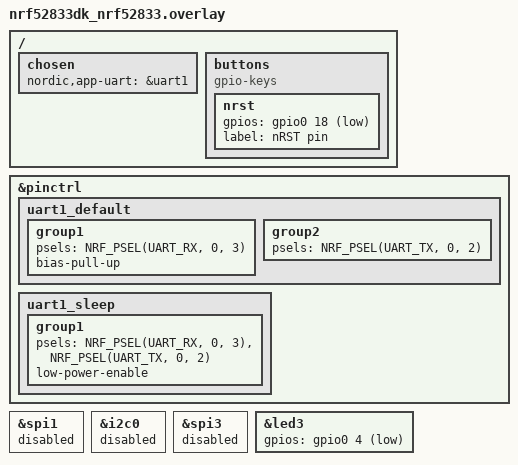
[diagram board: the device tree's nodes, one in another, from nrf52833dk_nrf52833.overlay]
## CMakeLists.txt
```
# SPDX-License-Identifier: Apache-2.0

cmake_minimum_required(VERSION 3.20.0)

set(CMAKE_EXPORT_COMPILE_COMMANDS ON)

# NOTE: Add module paths variable
set(QPC ${CMAKE_CURRENT_SOURCE_DIR}/qpc)                                    # QPC framework
set(APP_UART ${CMAKE_CURRENT_SOURCE_DIR}/ncs-uart-handler/modules/app_uart) # Async UART lib

# Append to Zephyr extra modules
#####################################################
find_package(Zephyr REQUIRED HINTS $ENV{ZEPHYR_BASE})
project(zephyr_obd)

target_sources(app PRIVATE src/main.c)

# Custom files and folders
target_sources(app PRIVATE
src/ble/bluetoothle.c
    
    src/ble/bluetoothle.c
    src/ble/ble_gatt.c
    src/driver/hal.c
    src/driver/hal_adc.c
    src/driver/hal_gpio.c
    src/driver/hal_i2c.c
    src/driver/hal_pwm.c
    src/driver/hal_uart.c
)

zephyr_library_include_directories(src/ble)
zephyr_library_include_directories(src/driver)
```

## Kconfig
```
source "Kconfig.zephyr"

config BOARD_ENABLE_FEM
bool "FEM enabled"
default y
select MPSL_FEM_GENERIC_TWO_CTRL_PINS_SUPPORT
```

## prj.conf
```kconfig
# Enable compiler output color
CONFIG_COMPILER_COLOR_DIAGNOSTICS=y

# Stack size configs
CONFIG_SYSTEM_WORKQUEUE_STACK_SIZE=3072
CONFIG_MAIN_STACK_SIZE=4096
CONFIG_ISR_STACK_SIZE=4096
# Debug configs
CONFIG_ASSERT=y
CONFIG_RESET_ON_FATAL_ERROR=n

CONFIG_DEBUG=y
CONFIG_DEBUG_OPTIMIZATIONS=y
CONFIG_DEBUG_THREAD_INFO=y

CONFIG_THREAD_NAME=y
CONFIG_THREAD_ANALYZER=y

CONFIG_TRACING=y
CONFIG_TRACING_BACKEND_RAM=y

CONFIG_SEGGER_SYSTEMVIEW=y
CONFIG_USE_SEGGER_RTT=y

# Logger configs
CONFIG_LOG=y
CONFIG_LOG_MODE_IMMEDIATE=y
CONFIG_LOG_BACKEND_RTT=n
CONFIG_LOG_BACKEND_UART=y
CONFIG_LOG_BACKEND_SHOW_COLOR=y
CONFIG_LOG_BACKEND_FORMAT_TIMESTAMP=y

# Bluetooth configs 
CONFIG_BT=y
CONFIG_BT_LL_SW_SPLIT=y
CONFIG_BT_LL_SOFTDEVICE=y
CONFIG_BT_MAX_CONN=1
CONFIG_BT_CTLR_TX_PWR_PLUS_8=y

CONFIG_BT_PERIPHERAL=y
CONFIG_BT_DEVICE_NAME="OBD-BLE"

CONFIG_BT_RX_STACK_SIZE=4096
CONFIG_BT_HCI_TX_STACK_SIZE=4096


# BLE NUS SERVICE
CONFIG_BT_NUS=y



# Driver configs
CONFIG_PWM=y
CONFIG_SERIAL=y
CONFIG_UART_INTERRUPT_DRIVEN=y
    # Ring buffer used in UART driver implementation
CONFIG_RING_BUFFER=y 
    # Heap memory pool size used by UART driver
CONFIG_HEAP_MEM_POOL_SIZE=1024 
CONFIG_ADC=y
CONFIG_I2C=y

# Turn off nRESET
CONFIG_GPIO_AS_PINRESET=n

# UART Asynchonous
# CONFIG_UART_ASYNC_API=y
# CONFIG_UART_1_ASYNC=y
# CONFIG_UART_1_NRF_HW_ASYNC=y
# CONFIG_UART_1_NRF_HW_ASYNC_TIMER=2
# CONFIG_NRFX_UARTE1=y
```

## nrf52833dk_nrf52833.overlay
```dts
&pinctrl {
    uart1_default: uart1_default {
		group1 {
			psels = <NRF_PSEL(UART_RX, 0, 3)>;
			bias-pull-up;
		};
		group2 {
			psels = <NRF_PSEL(UART_TX, 0, 2)>;
		};
	};

	uart1_sleep:
     uart1_sleep {
		group1 {
			psels = <NRF_PSEL(UART_RX, 0, 3)>,
				<NRF_PSEL(UART_TX, 0, 2)>;
			low-power-enable;
		};
	};
}; 

/ {
	chosen {
		nordic,app-uart = &uart1;
	};
	buttons {
		compatible = "gpio-keys";
		nrst: nrst {
			gpios = <&gpio0 18 (GPIO_PULL_UP | GPIO_ACTIVE_LOW)>;
			label = "nRST pin";
		};
	};


};
&spi1 {
    status = "disabled";
};

&i2c0 {
    status = "disabled";
};

&spi3 {
    status = "disabled";
};

/delete-node/ &{/pin-controller/pwm0_default/group1/};
/delete-node/ &{/pin-controller/pwm0_sleep/group1/};
&led3 {
    gpios = <&gpio0 4 (GPIO_ACTIVE_LOW)>;
};
```

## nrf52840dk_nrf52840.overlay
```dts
&pwm0 {
	status = "okay";
	ch0-pin = < 13 >;
	ch1-pin = < 11 >;
	ch2-pin = < 2 >;
	ch3-pin = < 15 >;
	/delete-property/ ch0-inverted;
};

&adc {
	status = "okay";
	io-channels = <&adc 0>, <&adc 1>, <&adc 2>, <&adc 3>, <&adc 4>, <&adc 5>, <&adc 6>, <&adc 7>;
};

&uart1 {
	status = "disabled";
};

/ {

    pwmleds {
		compatible = "pwm-leds";
		pwm_led0: pwm_led_0 {
			pwms =	<&pwm0 13>, 
					<&pwm0 11>,
					<&pwm0 2>,
					<&pwm0 15>;
		};
	};

	adc_pins: adc_pins {
		compatible = "arduino,uno-adc"; // Custom compatible, ignore this line
		#io-channel-cells = <1>;
		// Mapping ADC channels to pins
		// Format < [adc channel] &adc [IO pin number]>
		io-channel-map = 
				<0 &adc 2>,	 /* A0 = P0.2 */
				<1 &adc 3>,	 /* A1 = P0.4 */
				<2 &adc 4>,	 /* A2 = P0.2 */
				<3 &adc 5>,	 /* A3 = P0.2 */
				<4 &adc 28>, /* A4 = P0.28 */
				<5 &adc 29>, /* A5 = P0.29 */
				<6 &adc 30>, /* A6 = P0.30 */
				<7 &adc 31>; /* A7 = P0.31 */
	};

};
```

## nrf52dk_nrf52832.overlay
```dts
&pwm0 {
	status = "okay";
	ch0-pin = < 2 >;
	ch1-pin = < 11 >;
	ch2-pin = < 14 >;
	ch3-pin = < 15 >;
	/delete-property/ ch0-inverted;
};

&adc {
	status = "okay";
	io-channels = <&adc 0>, <&adc 1>, <&adc 2>, <&adc 3>, <&adc 4>, <&adc 5>, <&adc 6>, <&adc 7>;
};

&uart0 {
	status = "okay";
	tx-pin = < 19 >;
	rx-pin = < 20 >;
	/delete-property/ cts-pin;
	/delete-property/ rts-pin;
};

&spi1 {
	status = "disabled";
};

&spi2 {
	status = "disabled";
};

&i2c0 {
    sda-pin = <23>;
    scl-pin = <22>;
};

/delete-node/ &led0;
/delete-node/ &led1;
/delete-node/ &led2;
/delete-node/ &led3;
/delete-node/ &button0;
/delete-node/ &button1;
/delete-node/ &button2;
/delete-node/ &button3;
/delete-node/ &sw_pwm;


/ {
	aliases {
		/delete-property/ led0;
		/delete-property/ led1;
		/delete-property/ led2;
		/delete-property/ led3;
		/delete-property/ sw0;
		/delete-property/ sw1;
		/delete-property/ sw2;
		/delete-property/ sw3;
		/delete-property/ bootloader-led0;

	};
	/delete-node/ leds;
	/delete-node/ buttons;

	pwmleds {
		compatible = "pwm-leds";
		pwm_led0: pwm_led_0 {
			pwms =	<&pwm0 2>, 
					<&pwm0 11>,
					<&pwm0 14>,
					<&pwm0 15>;
		};
	};

	adc_pins: adc_pins {
		compatible = "arduino,uno-adc"; // Custom compatible, ignore this line
		#io-channel-cells = <1>;
		// Mapping ADC channels to pins
		// Format < [adc channel] &adc [IO pin number]>
		io-channel-map = 
				<0 &adc 2>,	 /* A0 = P0.2 */
				<1 &adc 3>,	 /* A1 = P0.3 */
				<2 &adc 4>,	 /* A2 = P0.4 */
				<3 &adc 5>,	 /* A3 = P0.5 */
				<4 &adc 28>, /* A4 = P0.28 */
				<5 &adc 29>, /* A5 = P0.29 */
				<6 &adc 30>, /* A6 = P0.30 */
				<7 &adc 31>; /* A7 = P0.31 */
	};

};
```

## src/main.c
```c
#include <string.h>
#include <stddef.h>
#include <zephyr/types.h>


#include "hal.h"
#include "logging/log.h"
#define MODULE_NAME			        main
#define MODULE_LOG_LEVEL	        LOG_LEVEL_DBG
LOG_MODULE_REGISTER(MODULE_NAME, MODULE_LOG_LEVEL);


#define APP_TEST_BLE            (0)
#define APP_TEST_PWM            (0)
#define APP_TEST_ADC            (0)
#define APP_TEST_GPIO           (0)
#define APP_TEST_UART           (0)
#define APP_TEST_I2C            (1)


#if (APP_TEST_BLE != 0)
#include "ble\ble_gatt.h"
#include "ble\bluetoothle.h"

void* char1_read_cb(void* p_data, void* p_len)
{
    static char default_char_value[]="CHAR1_PAYLOAD";
    *(int*)p_len = strlen(default_char_value);
    return default_char_value;
}

void* char2_read_cb(void* p_data, void* p_len)
{
    static char default_char_value[]="CHAR2_PAYLOAD";
    *(int*)p_len = strlen(default_char_value);
    return default_char_value;
}

void* char3_read_cb(void* p_data, void* p_len)
{
    static char default_char_value[]="CHAR3_PAYLOAD";
    *(int*)p_len = strlen(default_char_value);
    return default_char_value;
}

void* char4_read_cb(void* p_data, void* p_len)
{
    static char default_char_value[]="CHAR4_PAYLOAD";
    *(int*)p_len = strlen(default_char_value);
    return default_char_value;
}

int char5_write_cb(void* p_data, void* p_len)
{
    // Dump receive data
    LOG_INF("char5_write_cb, recv %dB", *(int*)p_len);
    LOG_HEXDUMP_INF(p_data, *(int*)p_len, "raw_payload: ");
    return 0;
}

ble_custom_gatt_cb_t custom_service_app =
{
    .custom_char1_read_cb = &char1_read_cb,
    .custom_char2_read_cb = &char2_read_cb,
    .custom_char3_read_cb = &char3_read_cb,
    .custom_char4_read_cb = &char4_read_cb,
    .custom_char5_write_cb = &char5_write_cb,
};

void ble_test(void)
{
    LOG_INF("============== BLE testing =====================");
    ble_init(NULL);
    ble_custom_service_init(&custom_service_app);

    ble_set_adv_name("ITACHI-BLE");
    ble_adv_start();
    while(1)
    {
        k_msleep(500);
        char3_send_notify("HELLO THERE, IM 3", strlen("HELLO THERE, IM 3"));
        k_msleep(500);
        char4_send_notify("HELLO THERE, IM 4", strlen("HELLO THERE, IM 4"));
    }
    LOG_INF("============== BLE testing =====================");
}
#endif /* End of (APP_TEST_BLE != 0) */

#if (APP_TEST_PWM != 0)
int __InitPWM();
int hal__setDutyCycle(uint8_t channel_num, uint16_t dutyCycle_tenth);

void pwm_custom_task(void *pvParameters)
{
    __InitPWM();
    while(1)
    {
        // Test PWM APIS with max duty = 1000%
        // Increase the duty cycle of each pin 50% every 300ms
        for(uint16_t duty = 0; duty <= 1000; duty += 100)
        {
            hal__setDutyCycle(0, duty);
            hal__setDutyCycle(1, duty);
            hal__setDutyCycle(2, duty);
            hal__setDutyCycle(3, duty);
            k_msleep(500);
            if(duty == 1000)
            {
                k_msleep(2000);
                duty = 0;
            }
            else if(duty == 0)
                k_msleep(2000);
        }
    }
}
#endif /* End of (APP_TEST_PWM != 0) */

#if (APP_TEST_ADC != 0)
void adc_custom_task(void *pvParameters)
{
    // Read all ADC channels
    if(__InitADC() != 0)
    {
        LOG_ERR("Failed to init ADC");
    }

    while(1)
    {
        int adc_raw[8]={0};
        int adc_voltage[8]={0};
        for(uint8_t idx=0; idx < 8; idx++)
        {
            adc_voltage[idx] = hal__ADCReadMV(idx);
            if(adc_voltage[idx] == FAILURE)
            {
                LOG_ERR("Failed to read ADC channel %d", idx);
                continue;
            }
            else if(adc_voltage[idx] < 0)
            {
                LOG_WRN("ADC channel %d read value %d", idx, adc_voltage[idx]);
            }
            else
            {
                // Normal
            }
        }
        // RAW: [%d %d %d %d %d %d %d %d]\n", adc_raw[0], adc_raw[1], adc_raw[2], adc_raw[3], adc_raw[4], adc_raw[5], adc_raw[6], adc_raw[7]
        LOG_INF("ADC: [%d %d %d %d %d %d %d %d]\n", adc_voltage[0], adc_voltage[1], adc_voltage[2], adc_voltage[3], adc_voltage[4], adc_voltage[5], adc_voltage[6], adc_voltage[7]);
        // mV: [%d %d %d %d %d %d %d %d]\n", adc_voltage[0], adc_voltage[1], adc_voltage[2], adc_voltage[3], adc_voltage[4], adc_voltage[5], adc_voltage[6], adc_voltage[7]
        k_msleep(1000);
    }
}
#endif /* End of (APP_TEST_ADC != 0) */

#if (APP_TEST_I2C != 0)
#define DS3231_I2C_ADDR 	0x68
#define DS3231_REG_CONTROL 	0x0e
#define DS3231_REG_SECOND 	0x00
#define DS3231_REG_MINUTE 	0x01
#define DS3231_REG_HOUR  	0x02
#define DS3231_REG_DOW    	0x03


uint8_t DS3231_DecodeBCD(uint8_t bin) {
	return (((bin & 0xf0) >> 4) * 10) + (bin & 0x0f);
}

/**
 * @brief Encodes a decimal number to binaty-coded decimal for storage in registers.
 * @param dec Decimal number to encode.
 * @return Encoded binary-coded decimal value.
 */
uint8_t DS3231_EncodeBCD(uint8_t dec) {
	return (dec % 10 + ((dec / 10) << 4));
}


int8_t DS3231_GetRegByte(uint8_t regAddr) {
	uint8_t val;
    if (0 != hal__I2CREAD_uint8(0, DS3231_I2C_ADDR, regAddr, &val))
    {
        LOG_ERR("I2C Read address 0x%02x failed", regAddr);
        return -1;
    }
    else
    {
        LOG_INF("I2C Read address 0x%02x: %d", regAddr, val);
    }
	return val;
}

int8_t DS3231_SetRegByte(uint8_t regAddr, uint8_t val) {
    if (0 != hal__I2CWRITE_uint8(0, DS3231_I2C_ADDR, regAddr, val))
    {
       LOG_ERR("I2C Write address 0x%02x failed", regAddr);
        return -1;
    }
    else
    {
        LOG_INF("I2C Write address 0x%02x: %d", regAddr, val);
    }
    return 0;
}

/**
 * @brief Gets the current hour in 24h format.
 * @return Hour in 24h format, 0 to 23.
 */
uint8_t DS3231_GetHour(void) {
	return DS3231_DecodeBCD(DS3231_GetRegByte(DS3231_REG_HOUR));
}

void DS3231_GetFullTime(uint8_t* hour, uint8_t* minute, uint8_t* second) {
    // Using hal__I2CREAD() to read 3 time bytes (SS:MM:HH)
    uint8_t data[3] = {0};
    if(hal__I2CREAD(0, DS3231_I2C_ADDR, DS3231_REG_SECOND, data, 3))
    // Decode the data
    *hour = DS3231_DecodeBCD(data[2]);
    *minute = DS3231_DecodeBCD(data[1]);
    *second = DS3231_DecodeBCD(data[0]);
    LOG_INF("Current time: %02d:%02d:%02d", *hour, *minute, *second);
}

void DS3231_SetFullTime(uint8_t hour, uint8_t min, uint8_t sec)
{
    // Encode the data
    uint8_t data[3] = {0};
    data[0] = DS3231_EncodeBCD(sec);
    data[1] = DS3231_EncodeBCD(min);
    data[2] = DS3231_EncodeBCD(hour);
    // Using hal__I2CWRITE() to write 3 time bytes (SS:MM:HH)
    if(hal__I2CWRITE(0, DS3231_I2C_ADDR, DS3231_REG_SECOND, data, 3) != 3)
    {
        LOG_ERR("Failed to set time");
    }
    else
    {
        LOG_INF("Set time: %02d:%02d:%02d", hour, min, sec);
    }
}

/**
 * @brief Set the current hour, in 24h format.
 * @param hour_24mode Hour in 24h format, 0 to 23.
 */
void DS3231_SetHour(uint8_t hour_24mode) {
	DS3231_SetRegByte(DS3231_REG_HOUR, DS3231_EncodeBCD(hour_24mode & 0x3f));
}

void i2c_custom_task(void *pvParameters)
{
    uint8_t data = 0;
    uint8_t i2c_num = 0;
    uint8_t addr = 0x68;
    uint8_t reg = 0x00;
    int test_hour = 1;

    while(1)
    {

        //Test I2C APIs with RTC RS3231
        if( true != hal__I2CEXISTS(0, 0x68))
        {
            LOG_ERR("I2C device does not exist");
        }
        else
        {
            LOG_INF("I2C device exists");
        }
        k_msleep(1000);

        // Get/Set/Get hour
        uint8_t cur_hour = DS3231_GetHour();
        LOG_INF("Current hour: %d", cur_hour);
        k_msleep(1000);

        DS3231_SetHour(test_hour++ + 1);
        k_msleep(1000);

        cur_hour = DS3231_GetHour();
        LOG_INF("Current hour: %d", cur_hour);
        k_msleep(1000);

        // Set full time use
        uint8_t hour = 10;
        uint8_t minute = 11;
        uint8_t second = 12;
        DS3231_SetFullTime(hour, minute, second);
        for(uint8_t count=0; count<20; count++)
        {
            DS3231_GetFullTime(&hour, &minute, &second);
            k_msleep(1000);
        }
    }
}
#endif /* End of (APP_TEST_I2C == 1) */


#if (APP_TEST_GPIO!= 0)
uint8_t io_test_pins[]={13, 11, 2, 15};
void gpio_custom__task(void *pvParameters)
{
    // Test pin as outputs
    for(uint8_t idx=0; idx < ARRAY_SIZE(io_test_pins); idx++)
    {
        hal__setState(io_test_pins[idx], 1);
    }

    for(uint8_t idx=0; idx < ARRAY_SIZE(io_test_pins); idx++)
    {
        hal__setLow(io_test_pins[idx]);
        k_msleep(1000);
    }

    // Turn on each pin for 1 second and then of 1 every 1 sec
    for(uint8_t idx=0; idx < ARRAY_SIZE(io_test_pins); idx++)
    {
        hal__setHigh(io_test_pins[idx]);
        k_msleep(1000);
    }

    // Set test pins as input
    for(uint8_t idx=0; idx < ARRAY_SIZE(io_test_pins) - 1; idx++)
    {
        hal__setState(io_test_pins[idx], 0);
    }
    hal__setState(io_test_pins[ARRAY_SIZE(io_test_pins)-1], 2);

    while(1)
    {
        LOG_INF("============== GPIO input =====================");
        // Read pin state
        for(uint8_t idx=0; idx < ARRAY_SIZE(io_test_pins); idx++)
        {
            LOG_INF("Pin %d state: %d", io_test_pins[idx], hal__read(io_test_pins[idx]));
        }
        k_msleep(1000);
        LOG_INF("============== GPIO input =====================\r\n ");
    }
}
#endif /* End of (APP_TEST_GPIO!= 0) */

#if (APP_TEST_UART != 0)
void uart_custom_task(void* p_param)
{
    int status = __InitUART();
    if(status != 0)
    {
        LOG_ERR("Failed to init UART with error code %d", status);
        return;
    }
    while(1)
    {
        int size = hal__UARTAvailable(0);
        if(size > 0)
        {
            uint8_t data[128]={0};
            hal__UARTRead(0, data, size);
            LOG_INF("UART0 recv %dB", size);
            // Echo back
            hal__UARTWrite(0, data, size);
            LOG_HEXDUMP_INF(data, size, "UART0 recv: ");
        }

        size = hal__UARTAvailable(1);
        if(size > 0)
        {
            uint8_t data[128]={0};
            hal__UARTRead(1, data, size);
            LOG_INF("UART1 recv %dB", size);
            // Echo back
            hal__UARTWrite(1, data, size);
            LOG_HEXDUMP_INF(data, size, "UART1 recv: ");
        }
        k_msleep(1000);
    }
}
#endif /* End of (APP_TEST_UART != 0) */

void main(void)
{
    if (SUCCESS != hal__init())
    {
        LOG_ERR("Failed to init HAL");
        return;
    }
#if (APP_TEST_BLE != 0)
    ble_test();
#endif /* End of (APP_TEST_BLE != 0) */

#if (APP_TEST_GPIO != 0)
    gpio_custom__task(NULL);
#endif /* End of (APP_TEST_GPIO != 0) */

#if (APP_TEST_PWM != 0)
    pwm_custom_task(NULL);
#endif /* End of (APP_TEST_PWM != 0) */

#if (APP_TEST_ADC != 0 )
    adc_custom_task(NULL);
#endif /* End of (APP_TEST_ADC != 0 ) */

#if (APP_TEST_UART != 0)
    uart_custom_task(NULL);
#endif /* End of (APP_TEST_UART != 0) */

#if (APP_TEST_I2C != 0)
    i2c_custom_task(NULL);
#endif /* End of (APP_TEST_I2C != 0) */

    while (1)
    {
        k_msleep(300);
    }
}
```
